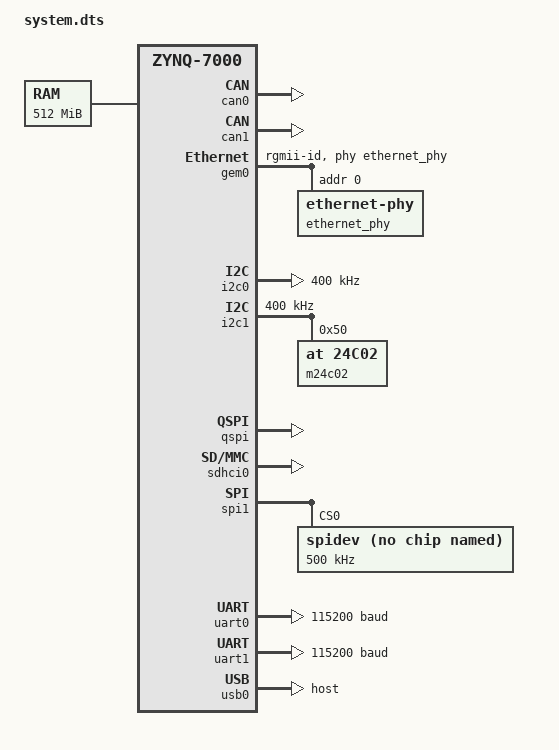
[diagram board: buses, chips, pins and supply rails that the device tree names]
/*
 * CAUTION: This file is automatically generated by Xilinx.
 * Version:  
 * Today is: Sun Aug 30 11:31:46 2015
*/


/dts-v1/;
/include/ "zynq-7000.dtsi"
/include/ "pl.dtsi"
/ {
	cpus {
		cpu@0 {
			operating-points = <650000 1000000 325000 1000000>;
		};
	};
	chosen {
		bootargs = "cma=64M console=ttyPS1,115200 root=/dev/mmcblk0p2 rw earlyprintk rootfstype=ext4 rootwait devtmpfs.mount=0";
	};
	aliases {
		ethernet0 = &gem0;
		serial0 = &uart0;
		serial1 = &uart1;
	};
	memory {
		device_type = "memory";
		reg = <0x0 0x20000000>;
	};
};
&can0 {
	status = "okay";
};

&can1 {
    status = "okay";
};
&gem0 {
    status = "okay";
    phy-mode = "rgmii-id";
    phy-handle = <&ethernet_phy>;
    ethernet_phy: ethernet-phy@0 {
        reg = <0>;
    };
};
&gpio0 {
	emio-gpio-width = <64>;
	gpio-mask-high = <0x0>;
	gpio-mask-low = <0x5600>;
};
&i2c0 {
	clock-frequency = <400000>;
	status = "okay";
};
&i2c1 {
	clock-frequency = <400000>;
	status = "okay";
    m24c02@50{
        compatible = "at,24c02";
        reg = <0x50>;
    };
};
&intc {
	num_cpus = <2>;
	num_interrupts = <96>;
};
&qspi {
	is-dual = <0>;
	num-cs = <1>;
	status = "okay";
};
&sdhci0 {
	clock-frequency = <50000000>;
	status = "okay";
};
&spi1 {
	is-decoded-cs = <0>;
	num-cs = <1>;
	status = "okay";
    spidev: spidev@0 {
        compatible = "linux,spidev";
        spi-max-frequency = <500000>;
        reg = <0>;
    };
};
&uart0 {
	current-speed = <115200>;
	device_type = "serial";
	port-number = <1>;
	status = "okay";
};
&uart1 {
	current-speed = <115200>;
	device_type = "serial";
	port-number = <0>;
	status = "okay";
};
&usb0 {
	dr_mode = "host";
	phy_type = "ulpi";
	status = "okay";
};
&clkc {
	fclk-enable = <0x1>;
	ps-clk-frequency = <50000000>;
};
